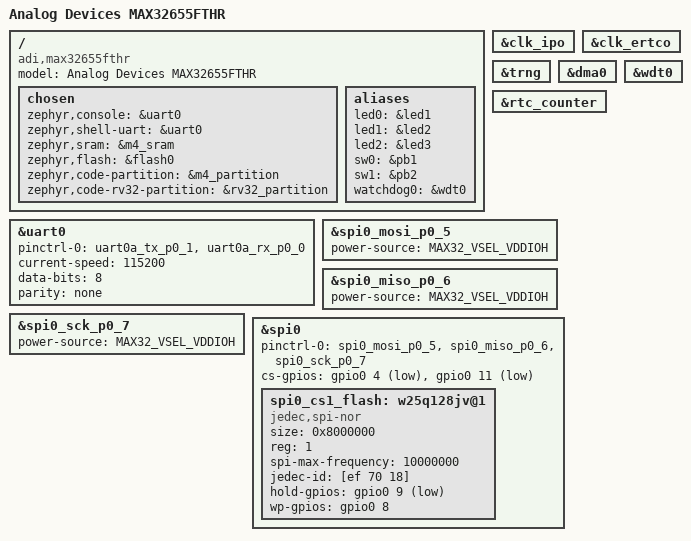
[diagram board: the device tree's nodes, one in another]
/*
 * Copyright (c) 2023-2025 Analog Devices, Inc.
 *
 * SPDX-License-Identifier: Apache-2.0
 */

/dts-v1/;

#include <adi/max32/max32655-m4.dtsi>
#include <adi/max32/max32655-pinctrl.dtsi>
#include "max32655fthr.dtsi"

/ {
	model = "Analog Devices MAX32655FTHR";
	compatible = "adi,max32655fthr";

	chosen {
		zephyr,console = &uart0;
		zephyr,shell-uart = &uart0;
		zephyr,sram = &m4_sram;
		zephyr,flash = &flash0;
		zephyr,code-partition = &m4_partition;
		zephyr,code-rv32-partition = &rv32_partition;
	};

	/* These aliases are provided for compatibility with samples */
	aliases {
		led0 = &led1;
		led1 = &led2;
		led2 = &led3;
		sw0 = &pb1;
		sw1 = &pb2;
		watchdog0 = &wdt0;
	};
};

&uart0 {
	pinctrl-0 = <&uart0a_tx_p0_1 &uart0a_rx_p0_0>;
	pinctrl-names = "default";
	current-speed = <115200>;
	data-bits = <8>;
	parity = "none";
	status = "okay";
};

&clk_ipo {
	status = "okay";
};

/*
 * ERTCO is required for counter RTC
 */
&clk_ertco {
	status = "okay";
};

&trng {
	status = "okay";
};

&dma0 {
	status = "okay";
};

&wdt0 {
	status = "okay";
};

&rtc_counter {
	status = "okay";
};

&spi0_mosi_p0_5 {
	power-source = <MAX32_VSEL_VDDIOH>;
};

&spi0_miso_p0_6 {
	power-source = <MAX32_VSEL_VDDIOH>;
};

&spi0_sck_p0_7 {
	power-source = <MAX32_VSEL_VDDIOH>;
};

&spi0 {
	status = "okay";
	pinctrl-0 = <&spi0_mosi_p0_5 &spi0_miso_p0_6 &spi0_sck_p0_7>;
	pinctrl-names = "default";
	cs-gpios = <&gpio0 4 (GPIO_ACTIVE_LOW | MAX32_GPIO_VSEL_VDDIOH)>,
		   <&gpio0 11 (GPIO_ACTIVE_LOW | MAX32_GPIO_VSEL_VDDIOH)>;

	spi0_cs1_flash: w25q128jv@1 {
		compatible = "jedec,spi-nor";
		/* 134217728 bits = 16 Mbytes */
		size = <0x8000000>;
		reg = <1>;
		spi-max-frequency = <10000000>;
		jedec-id = [ef 70 18];
		hold-gpios = <&gpio0 9 (GPIO_ACTIVE_LOW | MAX32_GPIO_VSEL_VDDIOH)>;
		wp-gpios = <&gpio0 8 (GPIO_ACTIVE_HIGH | MAX32_GPIO_VSEL_VDDIOH)>;
		status = "okay";
	};
};
